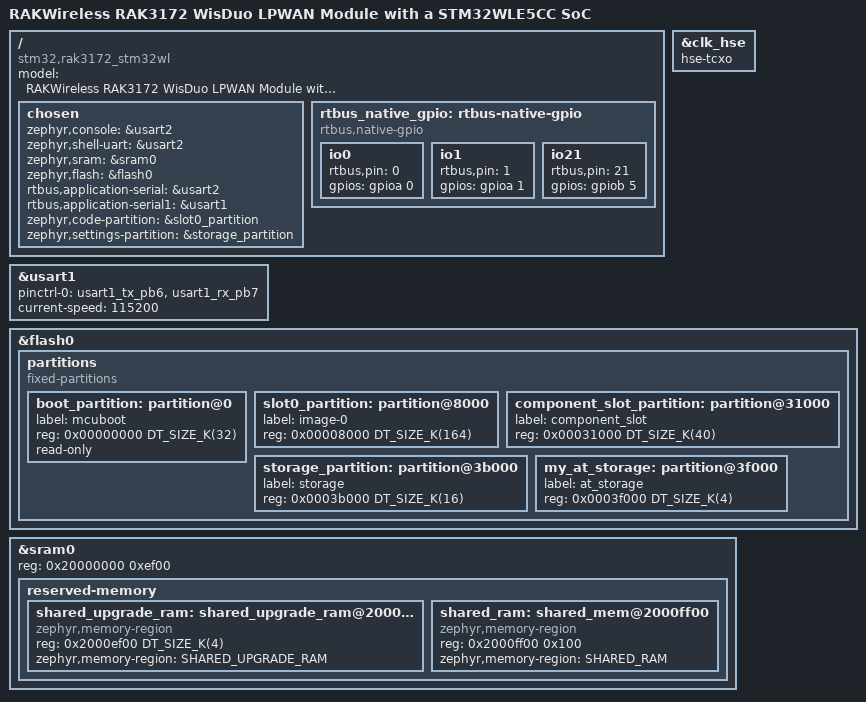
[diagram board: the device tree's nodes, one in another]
/ {
	model = "RAKWireless RAK3172 WisDuo LPWAN Module with a STM32WLE5CC SoC";
	compatible = "stm32,rak3172_stm32wl";

	chosen {
		zephyr,console = &usart2;
		zephyr,shell-uart = &usart2;
		zephyr,sram = &sram0;
		zephyr,flash = &flash0;
		rtbus,application-serial = &usart2;
		rtbus,application-serial1 = &usart1;
		zephyr,code-partition = &slot0_partition;
		zephyr,settings-partition = &storage_partition;
	};

	rtbus_native_gpio: rtbus-native-gpio {
		compatible = "rtbus,native-gpio";

		/*
		 * Application GPIO export map.
		 *
		 * Only board-owned pins that are safe for native applications should
		 * be listed here. Leaving this empty avoids exposing runtime,
		 * peripheral, wake, and low-power pins as raw GPIO ABI.
		 */

		io0 {
			rtbus,pin = <0>;
			gpios = <&gpioa 0 GPIO_ACTIVE_HIGH>;
		};

		io1 {
			rtbus,pin = <1>;
			gpios = <&gpioa 1 GPIO_ACTIVE_HIGH>;
		};

		io21 {
			rtbus,pin = <21>;
			gpios = <&gpiob 5 GPIO_ACTIVE_HIGH>;
		};
	};
};

&clk_hse {
	hse-tcxo;
};

&usart1 {
	pinctrl-0 = <&usart1_tx_pb6 &usart1_rx_pb7>;
	pinctrl-names = "default";
	current-speed = <115200>;
	status = "okay";
};

&flash0 {
	partitions {
		compatible = "fixed-partitions";
		#address-cells = <1>;
		#size-cells = <1>;
	/delete-node/ partition@0;
	/delete-node/ partition@8000;
	/delete-node/ partition@23000;
	/delete-node/ partition@34000;
	/delete-node/ partition@3e000;

		boot_partition: partition@0 {
			label = "mcuboot";
			reg = <0x00000000 DT_SIZE_K(32)>;
			read-only;
		};

	slot0_partition: partition@8000 {
		label = "image-0";
		reg = <0x00008000 DT_SIZE_K(164)>;
	};

	component_slot_partition: partition@31000 {
		label = "component_slot";
		reg = <0x00031000 DT_SIZE_K(40)>;
	};

	storage_partition: partition@3b000 {
		label = "storage";
		reg = <0x0003b000 DT_SIZE_K(16)>;
	};

	my_at_storage: partition@3f000 {
			label = "at_storage";
			reg = <0x0003f000 DT_SIZE_K(4)>;
		};
	};
};

&sram0 {
	reg = <0x20000000 0xef00>;

	reserved-memory {
		#address-cells = <1>;
		#size-cells = <1>;
		ranges;

		shared_upgrade_ram: shared_upgrade_ram@2000ef00 {
			compatible = "zephyr,memory-region";
			reg = <0x2000ef00 DT_SIZE_K(4)>;
			zephyr,memory-region = "SHARED_UPGRADE_RAM";
		};

		shared_ram: shared_mem@2000ff00 {
			compatible = "zephyr,memory-region";
			reg = <0x2000ff00 0x100>;
			zephyr,memory-region = "SHARED_RAM";
		};
	};
};
